AUTOSAR XML (schema 4-2-2)
package /ComponentTypes
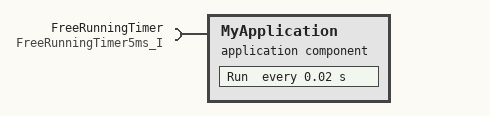
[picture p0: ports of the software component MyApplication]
  application sw component type MyApplication
    require port FreeRunningTimer: required-com-specs=[GetTime, IsTimerElapsed], required-interface=FreeRunningTimer5ms_I
    behavior MyApplication_InternalBehavior: port-api-option{enable-take-address=false, indirect-api=false, port=FreeRunningTimer}
      timing event TMT_Run: start-on-event=Run, period=0.02
      runnable Run
        sync call SC_FreeRunningTimer_GetTime: operation=FreeRunningTimer.GetTime, timeout=0
        sync call SC_FreeRunningTimer_IsTimerElapsed: operation=FreeRunningTimer.IsTimerElapsed, timeout=0
  swc implementation MyApplication_Implementation: programming-language=C, sw-version=1.0.0, used-code-generator=codeGen, vendor-id=99, behavior=MyApplication_InternalBehavior
    code-descriptors:
      code Default: artifact-descriptors=autosar-engineering-object={short-label=Default, category=SWSRC}
    resource consumption RsrcCons_MyApplication
      4 x memory section:
        CODE_INLINE: alignment=UNSPECIFIED, mem-class-symbol=memClassSymbol, options=INLINE, size=50, sw-addrmethod=CODE
        CODE: alignment=UNSPECIFIED, size=500, sw-addrmethod=CODE
        CONST: alignment=32, sw-addrmethod=CONST
        CALIB: alignment=8, sw-addrmethod=CALIB
package /AUTOSAR_MemMap/SwAddrMethods
  sw addr method CALIB
  sw addr method CODE
  sw addr method CONST
